# STM32MP23_CM33 register map
File version: 1.2
CPU: CM33 r0p1, little endian, MPU, FPU, vendor SysTick, 8 interrupt priority bits
Registers are 32-bit, read-write, reset 0x0 unless marked. A register's access mark holds for its fields unless they carry their own. Offsets are from the block's base; [hi:lo] are bit positions; {n}, {i} and the like mark numbered series; 'fields as' and 'values as' point back to an identical list.

## LTDC — LTDC register block
Base 0x48010000
Same registers: LTDC_S 0x58010000
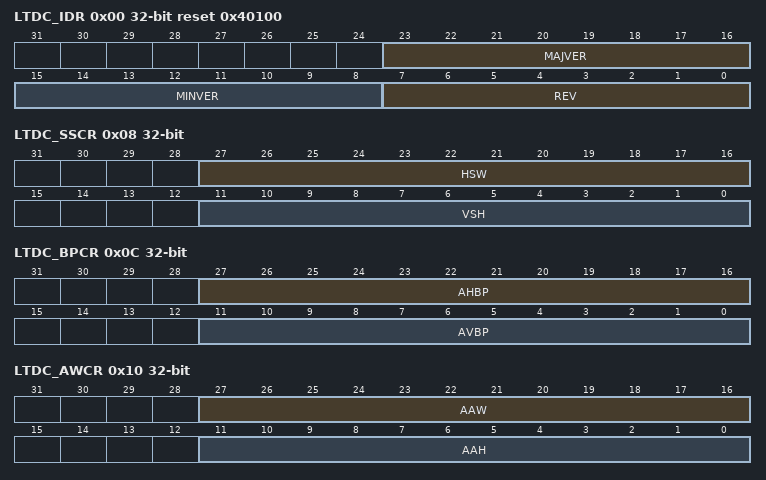
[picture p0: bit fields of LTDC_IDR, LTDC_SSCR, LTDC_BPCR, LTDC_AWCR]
0x00 LTDC_IDR ro reset 0x40100 — LTDC identification register
  [23:16] MAJVER — LTDC major version
  [15:8] MINVER — LTDC minor version
  [7:0] REV — Revision
0x04 LTDC_LCR ro reset 0x3 — LDTC layer count register
  [7:0] LNBR — Number of layers
0x08 LTDC_SSCR — LTDC synchronization size configuration register
  [27:16] HSW — Horizontal synchronization width (in units of pixel clock period)
  [11:0] VSH — Vertical synchronization height (in units of horizontal scan line)
0x0C LTDC_BPCR — LTDC back porch configuration register
  [27:16] AHBP — Accumulated horizontal back porch (in units of pixel clock period)
  [11:0] AVBP — Accumulated Vertical back porch (in units of horizontal scan line)
0x10 LTDC_AWCR — LTDC active width configuration register
  [27:16] AAW — Accumulated active width (in units of pixel clock period)
  [11:0] AAH — Accumulated active height (in units of horizontal scan line)
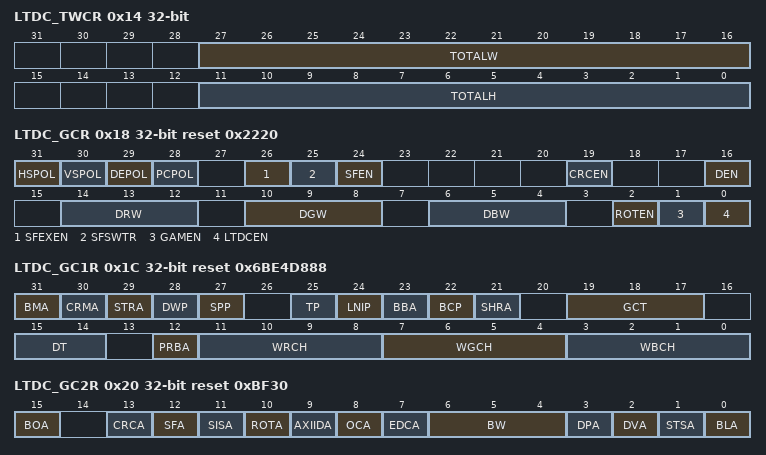
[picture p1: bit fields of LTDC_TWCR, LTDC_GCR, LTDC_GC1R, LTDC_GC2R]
0x14 LTDC_TWCR — LTDC total width configuration register
  [27:16] TOTALW — Total width (in units of pixel clock period)
  [11:0] TOTALH — Total height (in units of horizontal scan line)
0x18 LTDC_GCR reset 0x2220 — LTDC global control register
  [31] HSPOL — Horizontal synchronization polarity
    0=Horizontal synchronization polarity is active low; 1=Horizontal synchronization polarity is active high
  [30] VSPOL — Vertical synchronization polarity
    0=Vertical synchronization is active low; 1=Vertical synchronization is active high
  [29] DEPOL — Blanking (no data/pixel) polarity
    0=Blanking (no data/pixel) polarity is active low; 1=Blanking (no data/pixel) polarity is active high
  [28] PCPOL — Pixel clock polarity
    0=The pixel and sync data are generated at the rising-edge of the output LCD_CLK clock; 1=The pixel and sync data are generated at the falling-edge of the output LCD_CLK clock
  [26] SFEXEN — Single-frame mode: external trigger enable
    0=External trigger disabled; 1=External trigger enabled: a trigger on the external trigger generates one single frame
  [25] SFSWTR wo — Single-frame mode software trigger
    0=No action; 1=Triggers one frame
  [24] SFEN — Single-frame mode enable
    0=Single-frame disabled: a trigger (on SFSWTR or external) generates a continuous flow; 1=Single-frame enabled: a trigger (on SFSWTR or external) generates a single frame
  [19] CRCEN — CRC enable
    0=CRC disabled; 1=CRC enabled
  [16] DEN — Dither enable
    0=Dither disabled; 1=Dither enabled
  [14:12] DRW ro — Dither red width
  [10:8] DGW ro — Dither green width
  [6:4] DBW ro — Dither blue width
  [2] ROTEN — Rotation enable
    0=Rotation disabled; 1=Rotation enabled (for a pure visual rotation, the mirroring has to be activated)
  [1] GAMEN — Gamma correction enable
    0=Gamma correction disabled (pixels bypass the gamma operator); 1=Gamma correction enabled
  [0] LTDCEN — LTDC global enable
    0=LTDC disabled; 1=LTDC enabled
0x1C LTDC_GC1R ro reset 0x6BE4D888 — LTDC global configuration 1 register
  [31] BMA — Blind mode ability
  [30] CRMA — Configuration reading mode ability
  [29] STRA — Status register ability
  [28] DWP — Dither width programmability
  [27] SPP — Sync polarity programmability
  [25] TP — Timing programmability
  [24] LNIP — Line-IRQ: line position programmability
  [23] BBA — Background blending ability
  [22] BCP — Background color programmability (unique color blended as background)
  [21] SHRA — Shadow register ability
  [19:17] GCT — Gamma correction technique implemented
    0=No gamma; 1=Gamma with 256 samples; 2=Gamma with 8 interpolated segments
  [15:14] DT — Dithering technique implemented
    0=No dithering; 1=Ordered 4x4 Bayer; 2=Ordered 4x4 custom; 3=Pseudo-random LFSR
  [12] PRBA — Precise blending ability
  [11:8] WRCH — Width of red channel output
  [7:4] WGCH — Width of green channel output
  [3:0] WBCH — Width of blue channel output
0x20 LTDC_GC2R ro reset 0xBF30 — LTDC global configuration 2 register
  [15] BOA — Blending order ability
    0=Blending order fixed; 1=Blending order configurable
  [13] CRCA — CRC ability
    0=CRC no computation available; 1=CRC computation available
  [12] SFA — Single frame mode ability
    0=Single frame not available; 1=Single frame available
  [11] SISA — Second interrupt set ability
    0=Second interrupt set not available; 1=Second interrupt set available
  [10] ROTA — Rotation support ability
  [9] AXIIDA — AXIID ability
  [8] OCA — Output conversion ability (RGB to YCbCr)
  [7] EDCA — External display control ability
  [6:4] BW — Bus width (log2 of number of bytes)
    2=32-bit bus; 3=64-bit bus; 4=128-bit bus
  [3] DPA — Secondary RGB output port ability
  [2] DVA — Dual-view ability
  [1] STSA — Slave timings synchronization ability
  [0] BLA — Background layer ability (pixels of background layer are read from memory)
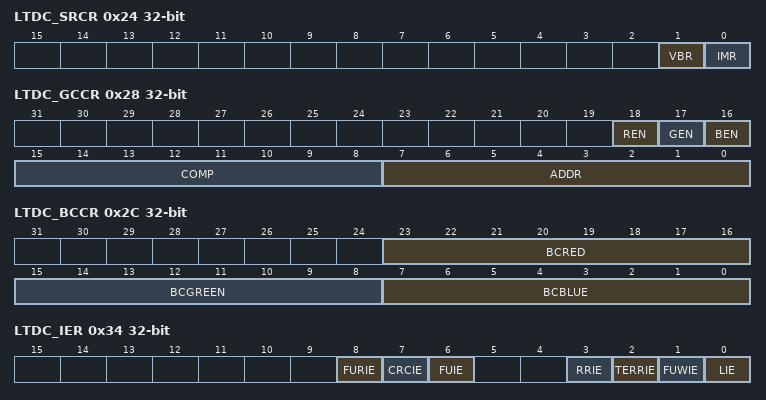
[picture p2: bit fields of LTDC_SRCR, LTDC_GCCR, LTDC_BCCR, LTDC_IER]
0x24 LTDC_SRCR — LTDC shadow reload configuration register
  [1] VBR — Vertical blanking reload request
    0=No effect; 1=The shadow registers are reloaded during the vertical blanking period (at the beginning of the first line after the active display area)
  [0] IMR — Immediate reload trigger
    0=No effect; 1=The shadow registers are reloaded immediately
0x28 LTDC_GCCR wo — LTDC gamma correction configuration register
  [18] REN — Write trigger to the red table
    0=No action; 1=COMP is written at ADDR in the red table
  [17] GEN — Write trigger to the green table
    0=No action; 1=COMP is written at ADDR in the green table
  [16] BEN — Write trigger to the blue table
    0=No action; 1=COMP is written at ADDR in the blue table
  [15:8] COMP — Color component to be written, in either (or all) the R,G,B tables
  [7:0] ADDR — Address of the R,G,B table where the COMP component is written
0x2C LTDC_BCCR — LTDC background color configuration register
  [23:16] BCRED — Background color red value
  [15:8] BCGREEN — Background color green value
  [7:0] BCBLUE — Background color blue value
0x34 LTDC_IER — LTDC interrupt enable register
  [8] FURIE — FIFO underrun at rotation interrupt enable
    0=FIFO underrun at rotation interrupt disabled; 1=FIFO underrun at rotation interrupt enabled
  [7] CRCIE — CRC error interrupt enable
    0=CRC error disabled; 1=CRC error interrupt enabled
  [6] FUIE — FIFO underrun interrupt enable
    0=FIFO underrun interrupt disabled; 1=FIFO underrun Interrupt enabled
  [3] RRIE — Register reload interrupt enable
    0=Register reload interrupt disabled; 1=Register reload interrupt enabled
  [2] TERRIE — Transfer error interrupt enable
    0=Transfer error interrupt disabled; 1=Transfer error interrupt enabled
  [1] FUWIE — FIFO underrun warning interrupt enable
    values as FUIE
  [0] LIE — Line interrupt enable
    0=line interrupt disabled; 1=line interrupt enabled
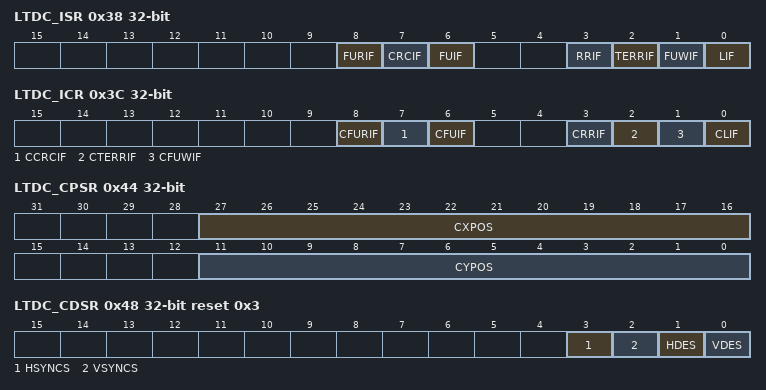
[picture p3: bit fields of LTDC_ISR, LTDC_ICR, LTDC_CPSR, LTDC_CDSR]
0x38 LTDC_ISR ro — LTDC interrupt status register
  [8] FURIF — FIFO underrun at rotation interrupt flag
    0=No FIFO underrun at rotation interrupt generated; 1=FIFO underrun at rotation interrupt generated
  [7] CRCIF — CRC error interrupt flag
    0=No CRC error interrupt generated; 1=CRC error interrupt generated when a bus error occurs
  [6] FUIF — FIFO underrun interrupt flag
    0=No FIFO underrun interrupt generated; 1=FIFO underrun interrupt generated, if one of the layer FIFOs is empty and many pixel data are read from the FIFO
  [3] RRIF — Register reload interrupt flag
    0=No register reload interrupt generated; 1=Register reload interrupt generated when a vertical blanking reload occurs (and the first line after the active area is reached)
  [2] TERRIF — Transfer error interrupt flag
    0=No transfer error interrupt generated; 1=Transfer error interrupt generated when a bus error occurs
  [1] FUWIF — FIFO underrun warning interrupt flag
    0=No FIFO underrun warning interrupt generated; 1=FIFO underrun warning interrupt generated, if one of the layer FIFO is empty and pixel data is read from the FIFO
  [0] LIF — Line interrupt flag
    0=No line interrupt generated; 1=Line interrupt generated when a programmed line is reached
0x3C LTDC_ICR wo — LTDC interrupt clear register
  [8] CFURIF — FIFO underrun at rotation interrupt flag clear
    0=No effect; 1=Clear FURIF flag in LTDC_ISR
  [7] CCRCIF — CRC error interrupt flag clear
    0=No effect; 1=Clear CRCIF flag in LTDC_ISR
  [6] CFUIF — FIFO underrun interrupt flag clear
    0=No effect; 1=Clear FUIF flag in LTDC_ISR
  [3] CRRIF — Register reload interrupt flag clear
    0=No effect; 1=Clear RRIF flag in LTDC_ISR
  [2] CTERRIF — Transfer error interrupt flag clear
    0=No effect; 1=Clear TERRIF flag in LTDC_ISR
  [1] CFUWIF — FIFO underrun warning interrupt flag clear
    0=No effect; 1=Clear FUWIF flag in LTDC_ISR
  [0] CLIF — Line-interrupt flag clear
    0=No effect; 1=Clear LIF flag in LTDC_ISR
0x40 LTDC_LIPCR — LTDC line interrupt position configuration register
  [11:0] LIPOS — Line interrupt position
0x44 LTDC_CPSR ro — LTDC current position status register
  [27:16] CXPOS — Current X position
  [11:0] CYPOS — Current Y position
0x48 LTDC_CDSR ro reset 0x3 — LTDC current display status register
  [all] fields
    0=Active low; 1=Active high
  [3] HSYNCS — Horizontal synchronization display status
  [2] VSYNCS — Vertical synchronization display status
  [1] HDES — Horizontal data enable display status
  [0] VDES — Vertical data enable display status
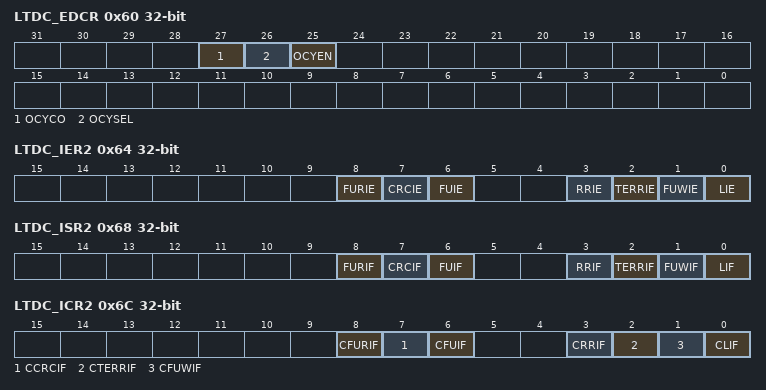
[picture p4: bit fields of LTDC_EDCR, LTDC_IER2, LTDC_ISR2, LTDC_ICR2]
0x60 LTDC_EDCR — LTDC external display control register
  [27] OCYCO — Output conversion to YCbCr 422
    0=Cb is output first (Y0Cb, then Y1Cr, Y2Cb and so on); 1=Cr is output first (Y0Cr, then Y1Cb, Y2Cr and so on)
  [26] OCYSEL — Output conversion to YCbCr 422
    0=Use ITU-R BT; 1=Use ITU-R BT
  [25] OCYEN — Output conversion to YCbCr 422 enable
    0=Conversion disabled; 1=Conversion enabled
0x64 LTDC_IER2 — LTDC interrupt enable register 2
  [8] FURIE — FIFO underrun at rotation interrupt enable
    values as LTDC_IER.FURIE
  [7] CRCIE — CRC error interrupt enable
    0=CRC error disabled; 1=CRC error interrupt enabled
  [6] FUIE — FIFO underrun interrupt enable
    values as LTDC_IER.FUIE
  [3] RRIE — Register reload interrupt enable
    values as LTDC_IER.RRIE
  [2] TERRIE — Transfer error interrupt enable
    values as LTDC_IER.TERRIE
  [1] FUWIE — FIFO underrun warning interrupt enable
    values as LTDC_IER.FUIE
  [0] LIE — Line interrupt enable
    0=Line interrupt disabled; 1=Line interrupt enabled
0x68 LTDC_ISR2 ro — LTDC interrupt status register 2
  [8] FURIF — FIFO underrun at rotation interrupt flag
    values as LTDC_ISR.FURIF
  [7] CRCIF — CRC Error interrupt flag
    values as LTDC_ISR.CRCIF
  [6] FUIF — FIFO underrun interrupt flag
    0=No FIFO underrun interrupt generated; 1=FIFO underrun interrupt generated, if one of the layer FIFO is empty and many pixel data are read from the FIFO
  [3] RRIF — Register reload interrupt flag
    values as LTDC_ISR.RRIF
  [2] TERRIF — Transfer error interrupt flag
    values as LTDC_ISR.TERRIF
  [1] FUWIF — FIFO underrun warning interrupt flag
    values as LTDC_ISR.FUWIF
  [0] LIF — Line interrupt flag
    values as LTDC_ISR.LIF
0x6C LTDC_ICR2 wo — LTDC interrupt clear register 2
  [8] CFURIF — Clear FIFO underrun at rotation interrupt flag
    0=No effect; 1=Clear the FURIF flag in LTDC_ISR2
  [7] CCRCIF — Clear the CRC error interrupt flag
    0=No effect; 1=Clear the CRCIF flag in LTDC_ISR2
  [6] CFUIF — Clear the FIFO underrun interrupt flag
    0=No effect; 1=Clear the FUIF flag in LTDC_ISR2
  [3] CRRIF — Clear register reload interrupt flag
    0=No effect; 1=Clear the RRIF flag in LTDC_ISR2
  [2] CTERRIF — Clear the transfer error interrupt flag
    0=No effect; 1=Clear the TERRIF flag in LTDC_ISR2
  [1] CFUWIF — Clear the FIFO underrun warning interrupt flag
    0=No effect; 1=Clear the FUWIF flag in LTDC_ISR2
  [0] CLIF — Clear the line interrupt flag
    0=No effect; 1=Clear the LIF flag in LTDC_ISR2
0x70 LTDC_LIPCR2 — LTDC line interrupt position configuration register 2
  [11:0] LIPOS — Line interrupt position
0x78 LTDC_ECRCR — LTDC expected CRC register
  [15:0] ECRC — Expected CRC of frame
0x7C LTDC_CCRCR ro — LTDC computed CRC register
  [15:0] CCRC — Computed CRC of frame
0x80 LTDC_RB0AR — LTDC rotation buffer 0 address register
  [31:0] ADDR — Address of the rotation buffer 0
0x84 LTDC_RB1AR — LTDC rotation buffer 1 address register
  [31:0] ADDR — Address of the rotation buffer 1
0x88 LTDC_RBPR — LTDC rotation buffer pitch register
  [11:0] PITCH — Pitch in bytes of the rotation buffers 0 and 1
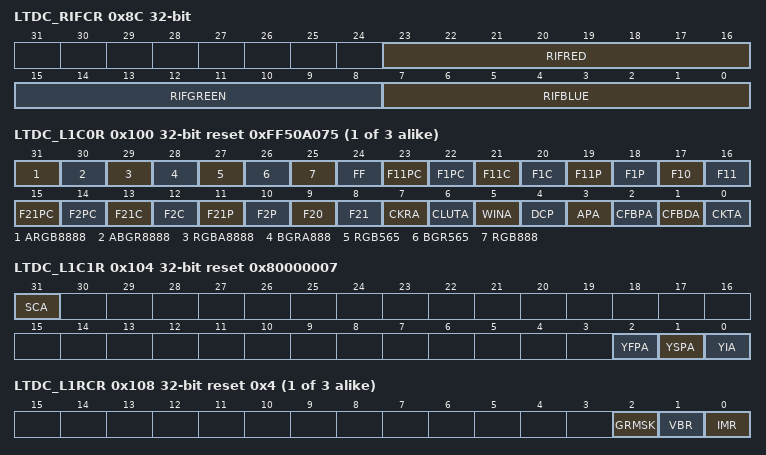
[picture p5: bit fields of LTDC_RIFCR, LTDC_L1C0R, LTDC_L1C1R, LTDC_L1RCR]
0x8C LTDC_RIFCR — LTDC rotation intermediate frame color register
  [23:16] RIFRED — Red component of the rotation intermediate frame
  [15:8] RIFGREEN — Green component of the rotation intermediate frame
  [7:0] RIFBLUE — Blue component of the rotation intermediate frame
0x90 LTDC_FUTR reset 0x10 — LTDC FIFO underrun threshold register
  [15:0] THRE — Threshold to trigger a FIFO underrun interrupt (per FIFO word, 64 bits)
{0x0+0x100*i} LTDC_L{i}C0R ro reset 0xFF50A075 (i=1..3) — LTDC layer {i} configuration 0 register
  [31] ARGB8888 — Pixel format, ability for argb8888
  [30] ABGR8888 — Pixel format, ability for abgr8888
  [29] RGBA8888 — Pixel format, ability for rgba8888
  [28] BGRA888 — Pixel format, ability for bgra8888
  [27] RGB565 — Pixel format, ability for rgb565
  [26] BGR565 — Pixel format, ability for bgr565
  [25] RGB888 — Pixel format, ability for rgb888
  [24] FF — Flexible pixel format, ability
  [23] F11PC — Blending factor 1, ability for 1.
  [22] F1PC — Blending factor 1, ability for pixel_alpha * constant_alpha
  [21] F11C — Blending factor 1, ability for 1.
  [20] F1C — Blending factor 1, ability for constant_alpha
  [19] F11P — Blending factor 1, ability for 1.
  [18] F1P — Blending factor 1, ability for pixel_alpha
  [17] F10 — Blending factor 1,ability for 0.
  [16] F11 — Blending factor 1, ability for 1.
  [15] F21PC — Blending factor 2, ability for 1.
  [14] F2PC — Blending factor 2, ability for pixel_alpha * constant_alpha
  [13] F21C — Blending factor 2, ability for 1.
  [12] F2C — Blending factor 2, ability for constant_alpha
  [11] F21P — Blending factor 2, ability for 1.
  [10] F2P — Blending factor 2, ability for pixel_alpha
  [9] F20 — Blending factor 2, ability for 0.
  [8] F21 — Blending factor 2, ability for 1.
  [7] CKRA — Color key replace ability
  [6] CLUTA — CLUT ability
  [5] WINA — Windowing ability
  [4] DCP — Default color programmability
  [3] APA — Alpha plane ability
  [2] CFBPA — Color frame buffer pitch ability
  [1] CFBDA — Color frame buffer duplication ability
  [0] CKTA — Color key transparency ability
0x104 LTDC_L1C1R ro reset 0x80000007 — LTDC layer 1 configuration 1 register
  [31] SCA — Scaling ability for this layer
    0=Scaling not available; 1=Scaling available
  [2] YFPA — YCbCr 420 full-planar ability for this layer
    0=Full planar not available; 1=Full planar available
  [1] YSPA — YCbCr 420 semi-planar ability for this layer
    0=Semi-planar not available; 1=Semi-planar available
  [0] YIA — YCbCr 422 interleaved ability for this layer
    0=Interleaved not available; 1=Interleaved available
{0x8+0x100*i} LTDC_L{i}RCR reset 0x4 (i=1..3) — LTDC layer {i} reload control register
  [2] GRMSK — Shadow reload control, global (centralized) reload masked
    0=Global reload masked for this layer (control from LTDC_SRCR disabled); 1=Global reload active for this layer (control from LTDC_SRCR enabled)
  [1] VBR — Vertical blanking reload request
    0=No effect; 1=Shadow registers are reloaded during the vertical blanking period (at the beginning of the first line after the active display area)
  [0] IMR wo — Immediate reload trigger
    0=No effect; 1=Shadow registers are reloaded immediately
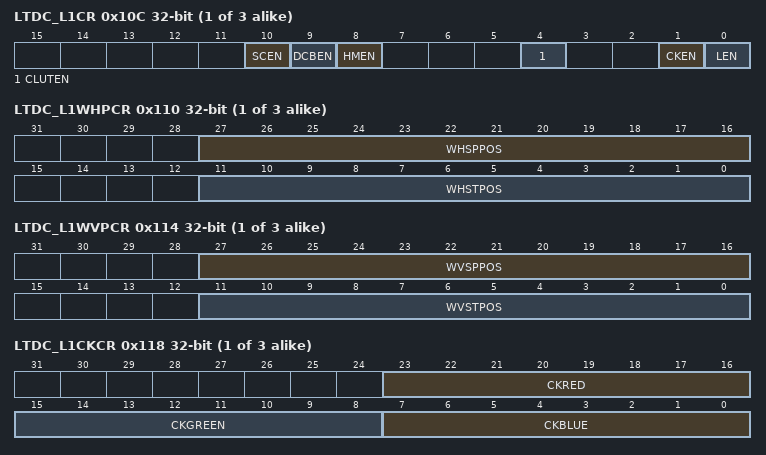
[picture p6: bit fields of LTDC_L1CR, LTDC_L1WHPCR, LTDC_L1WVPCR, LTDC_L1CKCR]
{0xC+0x100*i} LTDC_L{i}CR (i=1..3) — LTDC layer {i} control register
  [10] SCEN — Scaler enable
    0=Scaler disabled; 1=Scaler enabled
  [9] DCBEN — Default color blending enable
    0=Blending disabled; 1=Blending enabled
  [8] HMEN — Horizontal mirroring enable
    0=Mirror disabled; 1=Mirror enabled (if so, the color frame buffer start address has to be set to the last byte of the first line, so for instance: if line is 100 pixels, 24bpp, then address is set to 299)
  [4] CLUTEN — Color look-up table enable
    0=Color look-up table disabled; 1=Color look-up table enabled
  [1] CKEN — Color keying enable
    0=Color keying disabled; 1=Color keying enabled: if RGB matches, then the ARGB are set to 0
  [0] LEN — Layer enable
    0=Layer disabled; 1=Layer enabled
{0x10+0x100*i} LTDC_L{i}WHPCR (i=1..3) — LTDC layer {i} window horizontal position configuration register
  [27:16] WHSPPOS — Window horizontal stop position
  [11:0] WHSTPOS — Window horizontal start position
{0x14+0x100*i} LTDC_L{i}WVPCR (i=1..3) — LTDC layer {i} window vertical position configuration register
  [27:16] WVSPPOS — Window vertical stop position
  [11:0] WVSTPOS — Window vertical start position
{0x18+0x100*i} LTDC_L{i}CKCR (i=1..3) — LTDC layer {i} color keying configuration register
  [23:16] CKRED — Color key red value
  [15:8] CKGREEN — Color key green value
  [7:0] CKBLUE — Color key blue value
{0x1C+0x100*i} LTDC_L{i}PFCR (i=1..3) — LTDC layer {i} pixel format configuration register
  [2:0] PF — Pixel format
    0=ARGB8888 (32bpp); 1=ABGR8888 (32bpp); 2=RGBA8888 (32bpp); 3=BGRA8888 (32bpp); 4=RGB565 (16bpp, A=255); 5=BGR565 (16bpp, A=255); 6=RGB888 (24bpp packed, A=255); 7=Flexible pixel format selected (see Section52
{0x20+0x100*i} LTDC_L{i}CACR reset 0xFF (i=1..3) — LTDC layer {i} constant alpha configuration register
  [7:0] CONSTA — Constant alpha
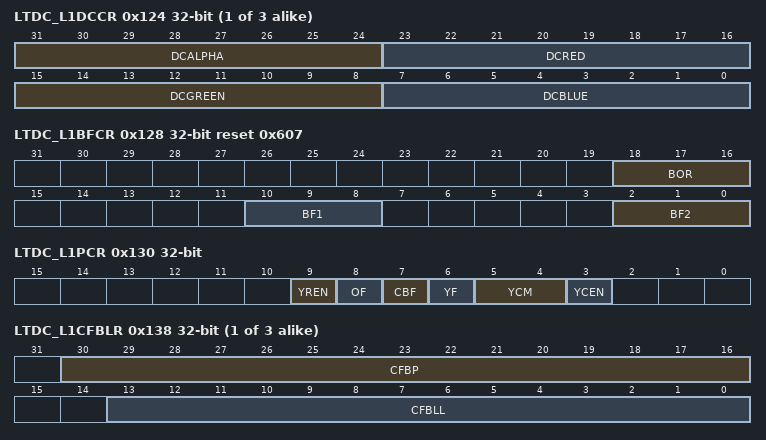
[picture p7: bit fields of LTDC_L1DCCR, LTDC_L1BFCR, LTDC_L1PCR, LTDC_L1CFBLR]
{0x24+0x100*i} LTDC_L{i}DCCR (i=1..3) — LTDC layer {i} default color configuration register
  [31:24] DCALPHA — Default color alpha
  [23:16] DCRED — Default color red
  [15:8] DCGREEN — Default color green
  [7:0] DCBLUE — Default color blue
0x128 LTDC_L1BFCR reset 0x607 — LTDC layer 1 blending factors configuration register
  [18:16] BOR — Blending order
    0=For the most background layer (usually hidden behind others); 7=For the most foreground layer (always visible, never hidden by any other)
  [10:8] BF1 — Default factor 1
    4=Constant alpha; 6=Pixel alpha x constant alpha
  [2:0] BF2 — Blending factor 2
    5=1 - constant alpha; 7=1 - (pixel alpha x constant alpha)
{0x2C+0x100*i} LTDC_L{i}BLCR (i=1..3) — LTDC layer {i} burst length configuration register
  [4:0] BL — Burst length
    0=maximum burst length (16 words 64 bits, thus 128 Bytes); 1=1 word (of 64bits) per burst; 16=16 words (of 64 bits) per burst
0x130 LTDC_L1PCR — LTDC layer 1 planar configuration register
  [9] YREN — Y rescale enable for the color dynamic range
    0=Rescaling disabled (input component thus assumed provided in 0 to 255); 1=Rescaling enabled (input component thus assumed provided in 16 to 235)
  [8] OF — Odd pixel first
    0=Odd pixel disabled (thus even pixel on byte 0); 1=Odd pixel enabled (thus odd pixel on byte 0)
  [7] CBF — Cb component first
    0=Cb disabled (thus Cr component is on byte 0 and 1); 1=Cb enabled (thus Cb component is on byte 0 and 1)
  [6] YF — Y component first
    0=Y component disabled (thus Cr or Cb component is on byte 0); 1=Y component enabled (thus Y component is on byte 0)
  [5:4] YCM — YCbCr conversion mode
    0=Interleaved 422 (Cb and Cr component are replicated horizontally for pixels P and P+1); 1=Semi-Planar 420: (Cb and Cr component are replicated horizontally and vertically; 2=Full-Planar 420: (Cb and Cr component are replicated horizontally and vertically
  [3] YCEN — YCbCr-to-RGB conversion enable
    0=Conversion disabled; 1=YCbCr conversion enabled, using the YCM setting above
{0x34+0x100*i} LTDC_L{i}CFBAR (i=1..3) — LTDC layer {i} color frame buffer address register
  [31:0] CFBADD — Color frame buffer start address
{0x38+0x100*i} LTDC_L{i}CFBLR (i=1..3) — LTDC layer {i} color frame buffer length register
  [30:16] CFBP — Color frame buffer pitch in bytes
  [13:0] CFBLL — Color frame buffer line length
{0x3C+0x100*i} LTDC_L{i}CFBLNR (i=1..3) — LTDC layer {i} color frame buffer line number register
  [11:0] CFBLNBR — Frame buffer line number
0x140 LTDC_L1AFBA0R — LTDC layer 1 auxiliary frame buffer address 0 register
  [31:0] AFBADD0 — Frame buffer start address
0x144 LTDC_L1AFBA1R — LTDC layer 1 auxiliary frame buffer address 1 register
  [31:0] AFBADD1 — Auxiliary frame buffer start address
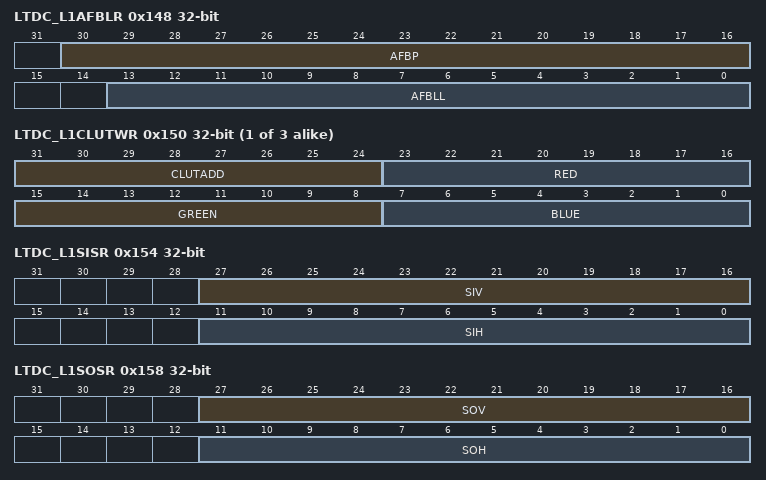
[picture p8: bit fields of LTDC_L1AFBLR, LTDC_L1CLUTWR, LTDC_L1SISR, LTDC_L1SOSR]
0x148 LTDC_L1AFBLR — LTDC layer 1 auxiliary frame buffer length register
  [30:16] AFBP — Auxiliary frame buffer pitch in bytes
  [13:0] AFBLL — Auxiliary frame buffer line length
0x14C LTDC_L1AFBLNR — LTDC layer 1 auxiliary frame buffer line number register
  [11:0] AFBLNBR — Auxiliary frame buffer line number
{0x50+0x100*i} LTDC_L{i}CLUTWR wo (i=1..3) — LTDC layer {i} CLUT write register
  [31:24] CLUTADD — CLUT address
  [23:16] RED — Red value
  [15:8] GREEN — Green value
  [7:0] BLUE — Blue value
0x154 LTDC_L1SISR — LTDC layer 1 scaler input size register
  [27:16] SIV — Scaler vertical input size (input height)
  [11:0] SIH — Scaler horizontal input size (input width)
0x158 LTDC_L1SOSR — LTDC layer 1 scaler output size register
  [27:16] SOV — Scaler vertical output size (output height)
  [11:0] SOH — Scaler horizontal output size (output width)
0x15C LTDC_L1SVSFR — LTDC layer 1 scaler vertical scaling factor register
  [15:0] SVF — Scaler vertical scaling factor
0x160 LTDC_L1SVSPR — LTDC layer 1 scaler vertical scaling phase register
  [15:0] SVP — Scaler vertical scaling factor
0x164 LTDC_L1SHSFR — LTDC layer 1 scaler horizontal scaling factor register
  [15:0] SHF — Scaler horizontal scaling factor
0x168 LTDC_L1SHSPR — LTDC layer 1 scaler horizontal scaling phase register
  [15:0] SHP — Scaler horizontal scaling phase
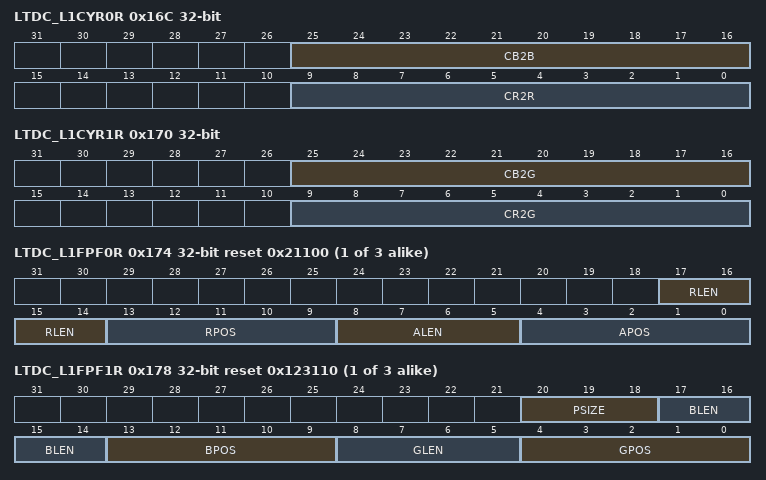
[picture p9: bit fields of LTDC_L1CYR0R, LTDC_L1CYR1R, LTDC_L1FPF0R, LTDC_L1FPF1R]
0x16C LTDC_L1CYR0R — LTDC layer 1 conversion YCbCr RGB 0 register
  [25:16] CB2B — Cb-to-Blue coefficient, with bits 9:8 as positive integer and 7:0 as decimals.
  [9:0] CR2R — Cr-to-Red coefficient, with bits 9:8 as positive integer and 7:0 as decimals.
0x170 LTDC_L1CYR1R — LTDC layer 1 conversion YCbCr RGB 1 register
  [25:16] CB2G — Cb-to-Green coefficient, with bits 9:8 as positive integer and 7:0 as decimals.
  [9:0] CR2G — Cr-to-Green coefficient, with bits 9:8 as positive integer and 7:0 as decimals.
{0x74+0x100*i} LTDC_L{i}FPF0R reset 0x21100 (i=1..3) — LTDC layer {i} flexible pixel format 0 register
  [17:14] RLEN — Width of the red component (in bits)
  [13:9] RPOS — Location of the red component inside the pixel memory word (in bits)
  [8:5] ALEN — Width of the alpha component (in bits)
  [4:0] APOS — Location of the alpha component inside the pixel memory word (in bits)
{0x78+0x100*i} LTDC_L{i}FPF1R reset 0x123110 (i=1..3) — LTDC layer {i} flexible pixel format 1 register
  [20:18] PSIZE — Pixel size (in bytes)
  [17:14] BLEN — Width of the blue component (in bits)
  [13:9] BPOS — Location of the blue component inside the pixel memory word (in bits)
  [8:5] GLEN — Width of the green component (in bits)
  [4:0] GPOS — Location of the green component inside the pixel memory word (in bits)
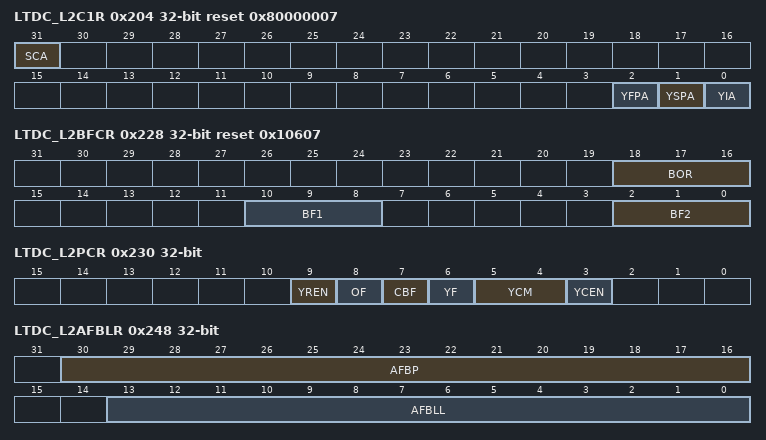
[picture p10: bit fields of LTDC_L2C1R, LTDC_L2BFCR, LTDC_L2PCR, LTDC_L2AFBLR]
0x204 LTDC_L2C1R ro reset 0x80000007 — LTDC layer 2 configuration 1 register
  fields as LTDC_L1C1R
0x228 LTDC_L2BFCR reset 0x10607 — LTDC layer 2 blending factors configuration register
  fields as LTDC_L1BFCR
0x230 LTDC_L2PCR — LTDC layer 2 planar configuration register
  fields as LTDC_L1PCR
0x240 LTDC_L2AFBA0R — LTDC layer 2 auxiliary frame buffer address 0 register
  [31:0] AFBADD0 — Frame buffer start address
0x244 LTDC_L2AFBA1R — LTDC layer 2 auxiliary frame buffer address 1 register
  [31:0] AFBADD1 — Auxiliary frame buffer start address
0x248 LTDC_L2AFBLR — LTDC layer 2 auxiliary frame buffer length register
  fields as LTDC_L1AFBLR
0x24C LTDC_L2AFBLNR — LTDC layer 2 auxiliary frame buffer line number register
  [11:0] AFBLNBR — Auxiliary frame buffer line number
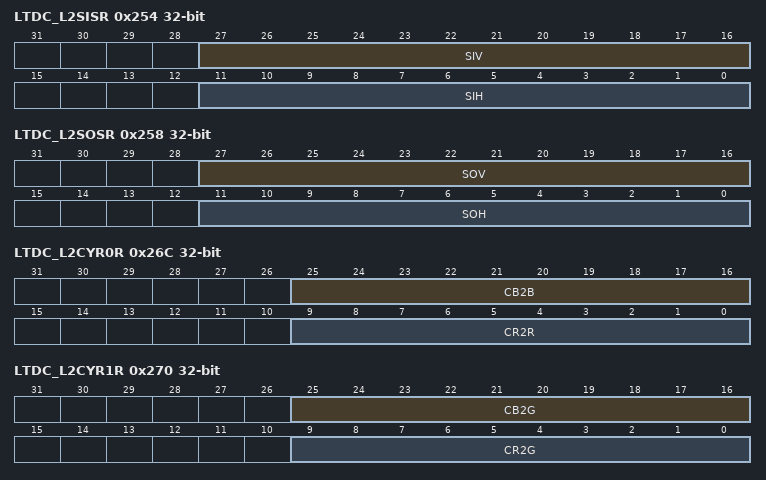
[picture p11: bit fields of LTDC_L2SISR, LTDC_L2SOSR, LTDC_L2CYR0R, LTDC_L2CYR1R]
0x254 LTDC_L2SISR — LTDC layer 2 scaler input size register
  fields as LTDC_L1SISR
0x258 LTDC_L2SOSR — LTDC layer 2 scaler output size register
  fields as LTDC_L1SOSR
0x25C LTDC_L2SVSFR — LTDC layer 2 scaler vertical scaling factor register
  [15:0] SVF — Scaler vertical scaling factor
0x260 LTDC_L2SVSPR — LTDC layer 2 scaler vertical scaling phase register
  [15:0] SVP — Scaler vertical scaling factor
0x264 LTDC_L2SHSFR — LTDC layer 2 scaler horizontal scaling factor register
  [15:0] SHF — Scaler horizontal scaling factor
0x268 LTDC_L2SHSPR — LTDC layer 2 scaler horizontal scaling phase register
  [15:0] SHP — Scaler horizontal scaling phase
0x26C LTDC_L2CYR0R — LTDC layer 2 conversion YCbCr RGB 0 register
  fields as LTDC_L1CYR0R
0x270 LTDC_L2CYR1R — LTDC layer 2 conversion YCbCr RGB 1 register
  fields as LTDC_L1CYR1R
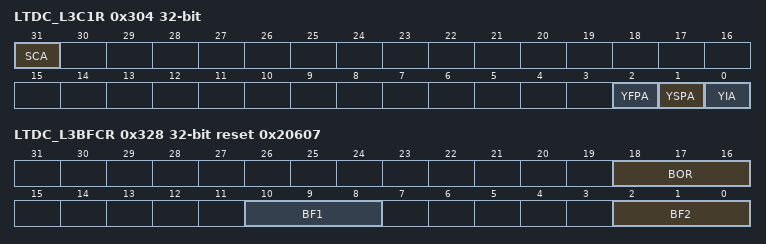
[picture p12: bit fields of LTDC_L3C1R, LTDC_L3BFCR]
0x304 LTDC_L3C1R ro — LTDC layer 3 configuration 1 register
  fields as LTDC_L1C1R
0x328 LTDC_L3BFCR reset 0x20607 — LTDC layer 3 blending factors configuration register
  fields as LTDC_L1BFCR
